# SPC1068 register map
File version: 20180100_70611510
CPU: CM3 r2p1, little endian, MPU, no FPU, 4 interrupt priority bits
Registers are 32-bit, read-write, reset 0x0 unless marked. A register's access mark holds for its fields unless they carry their own. Offsets are from the block's base; [hi:lo] are bit positions; {n}, {i} and the like mark numbered series.

## ECAP
Base 0x4000D000
0x00 TSCNT — Time-Stamp Counter Register
  [31:0] VAL — Active 32-bit counter register that is used as the capture time-base
0x04 CNTPHS — Counter Phase Offset Value Register
  [31:0] VAL — Counter phase value register that can be programmed for phase lag/lead
0x08 CAP0 — Capture Register 0
  [31:0] VAL — This register can be loaded by: - Time-Stamp(i.e., counter value) during a capture event - Software - may be useful for test purposes or initialization - APRD shadow register(i.e., CAP2) when used in APWM mode . NOTE: In APWM mode, writing to CAP0/CAP1 active registers also writes the same value to the corresponding shadow registers CAP2/CAP3. This emulates immediate mode. Writing to the shadow registers CAP2/CAP3 invokes the shadow mode.
0x0C CAP1 — Capture Register 1
  [31:0] VAL — This register can be loaded by: - Time-Stamp(i.e., counter value) during a capture event - Software - may be useful for test purposes or initialization - APRD shadow register(i.e., CAP3) when used in APWM mode . NOTE: In APWM mode, writing to CAP0/CAP1 active registers also writes the same value to the corresponding shadow registers CAP2/CAP3. This emulates immediate mode. Writing to the shadow registers CAP2/CAP3 invokes the shadow mode.
0x10 CAP2 — Capture Register 2
  [31:0] VAL — In Capture mode, this is a time-stamp capture register. In APWM mode, this is the period shadow (APRD) register. You update the PWM period value through this register. In this mode, CAP2 (APRD) shadows CAP0.
0x14 CAP3 — Capture Register 3
  [31:0] VAL — In Capture mode, this is a time-stamp capture register. In APWM mode, this is the compare shadow (ACMP) register. You update the PWM compare value via this register. In this mode, CAP3 (ACMP) shadows CAP1.
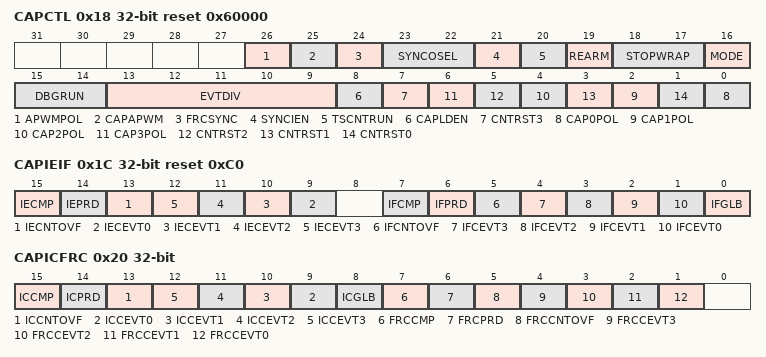
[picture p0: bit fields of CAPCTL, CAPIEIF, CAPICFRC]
0x18 CAPCTL reset 0x60000 — Capture Control Register
  [26] APWMPOL — APWM output polarity select. This is applicable only in APWM operating mode.
    0=ACTIVE_HIGH (Output is active high (i.e., Compare value defines high time)); 1=ACTIVE_LOW (Output is active low (i.e., Compare value defines low time))
  [25] CAPAPWM — Capture/APWM operating mode select
    0=CAPTURE_MODE (ECAP module operates in capture mode. This mode forces the following configuration: - Inhibits TSCNT resets via CNT = PRD event - Inhibits shadow loads on CAP0 and CAP1 registers - Permits user to enable CAP0-3 register load - CAPx/APWMx pin operates as a capture input); 1=APWM_MODE (ECAP module operates in APWM mode. This mode forces the following configuration: - Resets TSCNT on CNT = PRD event (period boundary - Permits shadow loading on CAP0 and CAP1 registers - Disables loading of time-stamps into CAP0-3 registers - CAPx/APWMx pin operates as a APWM output)
  [24] FRCSYNC — Software-forced Counter (TSCNT) Synchronizing. This provides a convenient software method to synchronize some or all ECAP time bases. In APWM mode, the synchronizing can also be done via the CNT = PRD event. . Note: Selection CNT = PRD is meaningful only in APWM mode; however, you can choose it in CAP mode if you find doing so useful.
    0=NO_EFFECT (Writing a zero has no effect. Reading always returns a zero.); 1=ENABLE (Writing a one forces a TSCNT shadow load of current ECAP module and any ECAP modules down-stream providing the SYNCOSEL bits are 00. After writing a 1, this bit returns to a zero.)
  [23:22] SYNCOSEL — Sync-Out Select
    0=SYNC_IN (Select sync-in event to be the sync-out signal (pass through)); 1=CNT_EQU_PRD (Select CNT = PRD event to be the sync-out signal); 3=DISABLE_SYNC_OUT (Disable sync out signal)
  [21] SYNCIEN — Counter (TSCNT) Sync-In select mode
    0=DISABLE (Disable sync-in option); 1=ENABLE (Enable counter (TSCNT) to be loaded from CNTPHS register upon either a SYNCI signal or a S/W force event)
  [20] TSCNTRUN — Time Stamp (TSCNT) Counter Stop (freeze) Control
    0=STOP_COUNTER (TSCNT stopped); 1=START_COUNTER (TSCNT free-running)
  [19] REARM — One-Shot Re-Arming Control, i.e. wait for stop trigger. Note: The re-arm function is valid in one shot or continuous mode.
    0=NO_EFFECT (Has no effect (reading always returns a 0)); 1=ENABLE (Arms the one-shot sequence as follows: 1) Resets the Mod4 counter to zero. 2) Unfreezes the Mod4 counter. 3) Enables capture register loads)
  [18:17] STOPWRAP — Stop value for one-shot mode. This is the number (between 0-3) of captures allowed to occur before the CAP (0-3) registers are frozen, i.e., capture sequence is stopped. Wrap value for continuous mode. This is the number (between 0-3) of the capture register in which the circular buffer wraps around and starts again. Notes: STOP_WRAP is compared to Mod4 counter and, when equal, 2 actions occur: - Mod4 counter is stopped (frozen) - Capture register loads are inhibited. In one-shot mode, further interrupt events are blocked until re-armed.
    {v}=ON_CAPTURE_EVENT{v} (Stop after Capture Event {v} in one-shot mode Wrap after Capture Event {v} in continuous mode) (v=0..3)
  [16] MODE — Continuous or one-shot mode control (applicable only in capture mode)
    0=CONTINOUS_MODE (Operate in continuous mode); 1=ONESHOT_MODE (Operate in one-Shot mode)
  [15:14] DBGRUN — ECAP counter behaviour when CPU is halted . Note: Debug operation and CPU fault exceptions both can cause CPU halted.
    0=STOP_IMMEDIATELY (TSCNT counter stops immediately when CPU is halted); 1=STOP_AT_ZERO (TSCNT counter runs until = 0 when CPU is halted); 2=KEEP_RUN (TSCNT counter is unaffected when CPU is halted)
  [13:9] EVTDIV — Event Filter prescale select
  [8] CAPLDEN — Enable Loading of CAP0-3 registers on a capture event
    0=CAPTURE_LOAD_DISABLE (Disable CAP0-3 register loads at capture event time); 1=CAPTURE_LOAD_ENABLE (Enable CAP0-3 register loads at capture event time)
  [7] CNTRST3 — Counter Reset on Capture Event 3
    0=NO_RESET_ON_CAPTURE (Do not reset counter on Capture Event 3 (absolute time stamp operation)); 1=RESET_ON_CAPTURE (Reset counter after Capture Event 3 time-stamp has been captured (used in difference mode operation))
  [2n] CAP{n}POL (n=0..3) — Capture Event {n} Polarity select
    0=TRIG_ON_RISING_EDGE (Capture Event {n} triggered on a rising edge (RE)); 1=TRIG_ON_FALLING_EDGE (Capture Event {n} triggered on a falling edge (FE))
  [5] CNTRST2 — Counter Reset on Capture Event 2
    0=NO_RESET_ON_CAPTURE (Do not reset counter on Capture Event 2 (absolute time stamp)); 1=RESET_ON_CAPTURE (Reset counter after Event 2 time-stamp has been captured (used in difference mode operation))
  [3] CNTRST1 — Counter Reset on Capture Event 1
    0=NO_RESET_ON_CAPTURE (Do not reset counter on Capture Event 1 (absolute time stamp)); 1=RESET_ON_CAPTURE (Reset counter after Event 1 time-stamp has been captured (used in difference mode operation))
  [1] CNTRST0 — Counter Reset on Capture Event 0
    0=NO_RESET_ON_CAPTURE (Do not reset counter on Capture Event 0 (absolute time stamp)); 1=RESET_ON_CAPTURE (Reset counter after Event 0 time-stamp has been captured (used in difference mode operation))
0x1C CAPIEIF reset 0xC0 — Capture Interrupt Enable and Flag Register
  [15] IECMP — Counter Equal Compare Interrupt Enable
    0=DISABLE (Disable Compare Equal as an Interrupt source); 1=ENABLE (Enable Compare Equal as an Interrupt source)
  [14] IEPRD — Counter Equal Period Interrupt Enable
    0=DISABLE (Disable Period Equal as an Interrupt source); 1=ENABLE (Enable Period Equal as an Interrupt source)
  [13] IECNTOVF — Counter Overflow Interrupt Enable
    0=DISABLE (Disabled counter Overflow as an Interrupt source); 1=ENABLE (Enable counter Overflow as an Interrupt source)
  [n+9] IECEVT{n} (n=0..3) — Capture Event {n} Interrupt Enable
    0=DISABLE (Disable Capture Event {n} as an Interrupt source); 1=ENABLE (Enable Capture Event {n} as an Interrupt source)
  [7] IFCMP ro — Compare Equal Compare Status Flag. This flag is active only in APWM mode.
    0=NOT_OCCUR (Indicates no event occurred); 1=OCCUR (Indicates the counter (TSCNT) reached the compare register value (ACMP))
  [6] IFPRD ro — Counter Equal Period Status Flag. This flag is only active in APWM mode.
    0=NOT_OCCUR (Indicates no event occurred); 1=OCCUR (Indicates the counter (TSCNT) reached the period register value (APRD) and was reset)
  [5] IFCNTOVF ro — Counter Overflow Status Flag. This flag is active in Capture and APWM mode.
    0=NOT_OCCUR (Indicates no event occurred); 1=OCCUR (Indicates the counter (TSCNT) has made the transition from FFFFFFFF to 00000000)
  [4] IFCEVT3 ro — Capture Event 3 Status Flag. This flag is only active in Capture mode.
    0=NOT_OCCUR (Indicates no event occurred); 1=OCCUR (Indicates the fourth event occurred at ECAPx pin)
  [3] IFCEVT2 ro — Capture Event 2 Status Flag. This flag is active only in Capture mode.
    0=NOT_OCCUR (Indicates no event occurred); 1=OCCUR (Indicates the third event occurred at ECAPx pin)
  [2] IFCEVT1 ro — Capture Event 1 Status Flag. This flag is only active in Capture mode.
    0=NOT_OCCUR (Indicates no event occurred); 1=OCCUR (Indicates the second event occurred at ECAPx pin)
  [1] IFCEVT0 ro — Capture Event 0 Status Flag. This flag is only active in Capture mode.
    0=NOT_OCCUR (Indicates no event occurred); 1=OCCUR (Indicates the first event occurred at ECAPx pin)
  [0] IFGLB ro — Global Interrupt Status Flag
    0=NOT_OCCUR (Indicates no interrupt generated); 1=OCCUR (Indicates that an interrupt was generated)
0x20 CAPICFRC — Capture Interrupt Clear and Force Register
  [15] ICCMP — Counter Equal Compare Status Flag
    0=NO_EFFECT (Writing a 0 has no effect. Always reads back a 0.); 1=CLEAR_CNT_EQU_COMP_FLAG (Writing a 1 clears the CNT=CMP flag condition)
  [14] ICPRD — Counter Equal Period Status Flag
    0=NO_EFFECT (Writing a 0 has no effect. Always reads back a 0.); 1=CLEAR_CNT_EQU_PRD_FLAG (Writing a 1 clears the CNT=PRD flag condition)
  [13] ICCNTOVF — Counter Overflow Status Flag
    0=NO_EFFECT (Writing a 0 has no effect. Always reads back a 0.); 1=CLEAR_CNT_OVERFLOW_FLAG (Writing a 1 clears the CNTOVF flag condition)
  [n+9] ICCEVT{n} (n=0..3) — Capture Event {n} Status Flag
    0=NO_EFFECT (Writing a 0 has no effect. Always reads back a 0.); 1=CLEAR (Writing a 1 clears the CEVT{n} flag condition)
  [8] ICGLB — Global Interrupt Clear Flag
    0=NO_EFFECT (Writing a 0 has no effect. Always reads back a 0.); 1=CLEAR_GLOBAL_INT_FLAG (Writing a 1 clears the INT flag and enable further interrupts to be generated if any of the event flags are set to 1)
  [7] FRCCMP — Force Counter Equal Compare Interrupt
    0=NO_EFFECT (No effect. Always reads back a 0.); 1=FORCE_CNT_EQU_COMP (Writing a 1 sets the CNT=CMP flag bit)
  [6] FRCPRD — Force Counter Equal Period Interrupt
    0=NO_EFFECT (No effect. Always reads back a 0.); 1=FORCE_CNT_EQU_PRD (Writing a 1 sets the CNT=PRD flag bit)
  [5] FRCCNTOVF — Force Counter Overflow
    0=NO_EFFECT (No effect. Always reads back a 0.); 1=FORCE_CNT_OVERFLOW (Writing a 1 sets the CNTOVF flag bit)
  [4] FRCCEVT3 — Force Capture Event 3
    0=NO_EFFECT (No effect. Always reads back a 0.); 1=FORCE (Writing a 1 sets the CEVT3 flag bit)
  [3] FRCCEVT2 — Force Capture Event 2
    0=NO_EFFECT (No effect. Always reads back a 0.); 1=FORCE (Writing a 1 sets the CEVT2 flag bit)
  [2] FRCCEVT1 — Force Capture Event 1
    0=NO_EFFECT (No effect. Always reads back a 0.); 1=FORCE (Writing a 1 sets the CEVT1 flag bit)
  [1] FRCCEVT0 — Force Capture Event 0
    0=NO_EFFECT (No effect. Always reads back a 0.); 1=FORCE (Sets the CEVT0 flag bit)
